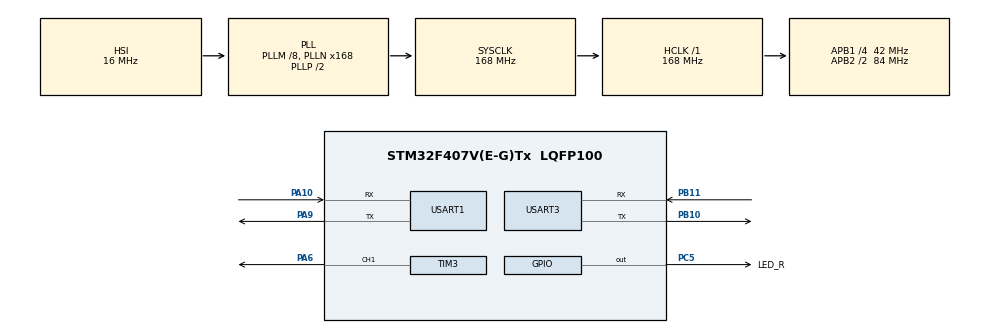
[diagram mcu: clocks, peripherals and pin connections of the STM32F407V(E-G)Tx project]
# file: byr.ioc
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Dma.Request0=USART1_RX
Dma.Request1=USART1_TX
Dma.Request2=USART3_RX
Dma.Request3=USART3_TX
Dma.USART1_RX.0.Direction=DMA_PERIPH_TO_MEMORY
Dma.USART1_RX.0.FIFOMode=DMA_FIFOMODE_DISABLE
Dma.USART1_RX.0.Instance=DMA2_Stream2
Dma.USART1_RX.0.MemDataAlignment=DMA_MDATAALIGN_BYTE
Dma.USART1_RX.0.MemInc=DMA_MINC_ENABLE
Dma.USART1_RX.0.Mode=DMA_CIRCULAR
Dma.USART1_RX.0.PeriphDataAlignment=DMA_PDATAALIGN_BYTE
Dma.USART1_RX.0.PeriphInc=DMA_PINC_DISABLE
Dma.USART1_RX.0.Priority=DMA_PRIORITY_LOW
Dma.USART1_TX.1.Direction=DMA_MEMORY_TO_PERIPH
Dma.USART1_TX.1.FIFOMode=DMA_FIFOMODE_DISABLE
Dma.USART1_TX.1.Instance=DMA2_Stream7
Dma.USART1_TX.1.MemDataAlignment=DMA_MDATAALIGN_BYTE
Dma.USART1_TX.1.MemInc=DMA_MINC_ENABLE
Dma.USART1_TX.1.Mode=DMA_NORMAL
Dma.USART1_TX.1.PeriphDataAlignment=DMA_PDATAALIGN_BYTE
Dma.USART1_TX.1.PeriphInc=DMA_PINC_DISABLE
Dma.USART1_TX.1.Priority=DMA_PRIORITY_LOW
Dma.USART3_RX.2.Direction=DMA_PERIPH_TO_MEMORY
Dma.USART3_RX.2.FIFOMode=DMA_FIFOMODE_DISABLE
Dma.USART3_RX.2.Instance=DMA1_Stream1
Dma.USART3_RX.2.MemDataAlignment=DMA_MDATAALIGN_BYTE
Dma.USART3_RX.2.MemInc=DMA_MINC_ENABLE
Dma.USART3_RX.2.Mode=DMA_CIRCULAR
Dma.USART3_RX.2.PeriphDataAlignment=DMA_PDATAALIGN_BYTE
Dma.USART3_RX.2.PeriphInc=DMA_PINC_DISABLE
Dma.USART3_RX.2.Priority=DMA_PRIORITY_LOW
Dma.USART3_TX.3.Direction=DMA_MEMORY_TO_PERIPH
Dma.USART3_TX.3.FIFOMode=DMA_FIFOMODE_DISABLE
Dma.USART3_TX.3.Instance=DMA1_Stream3
Dma.USART3_TX.3.MemDataAlignment=DMA_MDATAALIGN_BYTE
Dma.USART3_TX.3.MemInc=DMA_MINC_ENABLE
Dma.USART3_TX.3.Mode=DMA_NORMAL
Dma.USART3_TX.3.PeriphDataAlignment=DMA_PDATAALIGN_BYTE
Dma.USART3_TX.3.PeriphInc=DMA_PINC_DISABLE
Dma.USART3_TX.3.Priority=DMA_PRIORITY_LOW
Mcu.Family=STM32F4
Mcu.Name=STM32F407V(E-G)Tx
Mcu.Package=LQFP100
NVIC.DMA1_Stream1_IRQn=true\:0\:0\:false\:false\:true\:false\:true\:true
NVIC.DMA1_Stream3_IRQn=true\:0\:0\:false\:false\:true\:false\:true\:true
NVIC.DMA2_Stream2_IRQn=true\:0\:0\:false\:false\:true\:false\:true\:true
NVIC.DMA2_Stream7_IRQn=true\:0\:0\:false\:false\:true\:false\:true\:true
NVIC.PriorityGroup=NVIC_PRIORITYGROUP_4
NVIC.TIM4_IRQn=true\:2\:0\:true\:false\:true\:true\:true\:true
NVIC.USART1_IRQn=true\:3\:0\:true\:false\:true\:false\:true\:true
NVIC.USART3_IRQn=true\:0\:0\:false\:false\:true\:false\:true\:true
PA10.Mode=Asynchronous
PA10.Signal=USART1_RX
PA13.Mode=Serial_Wire
PA13.Signal=SYS_JTMS-SWDIO
PA14.Mode=Serial_Wire
PA14.Signal=SYS_JTCK-SWCLK
PA6.Signal=S_TIM3_CH1
PA9.Mode=Asynchronous
PA9.Signal=USART1_TX
PB10.Mode=Asynchronous
PB10.Signal=USART3_TX
PB11.Mode=Asynchronous
PB11.Signal=USART3_RX
PC14-OSC32_IN.Mode=LSE-External-Oscillator
PC14-OSC32_IN.Signal=RCC_OSC32_IN
PC15-OSC32_OUT.Mode=LSE-External-Oscillator
PC15-OSC32_OUT.Signal=RCC_OSC32_OUT
PC5.GPIO_Label=LED_R
PC5.Signal=GPIO_Output
PH0-OSC_IN.Mode=HSE-External-Oscillator
PH0-OSC_IN.Signal=RCC_OSC_IN
PH1-OSC_OUT.Mode=HSE-External-Oscillator
PH1-OSC_OUT.Signal=RCC_OSC_OUT
ProjectManager.HeapSize=0x1000
ProjectManager.StackSize=0x1200
ProjectManager.TargetToolchain=CMake
RCC.48MHZClocksFreq_Value=84000000
RCC.AHBFreq_Value=168000000
RCC.APB1CLKDivider=RCC_HCLK_DIV4
RCC.APB1Freq_Value=42000000
RCC.APB1TimFreq_Value=84000000
RCC.APB2CLKDivider=RCC_HCLK_DIV2
RCC.APB2Freq_Value=84000000
RCC.APB2TimFreq_Value=168000000
RCC.CortexFreq_Value=168000000
RCC.HCLKFreq_Value=168000000
RCC.HSE_VALUE=25000000
RCC.HSI_VALUE=16000000
RCC.PLLM=8
RCC.PLLN=168
RCC.SYSCLKFreq_VALUE=168000000
RCC.SYSCLKSource=RCC_SYSCLKSOURCE_PLLCLK
RCC.VCOOutputFreq_Value=336000000
SH.S_TIM3_CH1.0=TIM3_CH1,PWM Generation1 CH1
TIM3.Channel-PWM\ Generation1\ CH1=TIM_CHANNEL_1
TIM3.Period=999
TIM3.Prescaler=0
TIM3.Pulse-PWM\ Generation1\ CH1=4999
TIM4.ClockDivision=TIM_CLOCKDIVISION_DIV4
TIM4.Period=999
TIM4.Prescaler=20999
USART1.VirtualMode=VM_ASYNC
USART3.VirtualMode=VM_ASYNC
VP_TIM3_VS_ClockSourceINT.Mode=Internal
VP_TIM4_VS_ClockSourceINT.Mode=Internal
board=custom

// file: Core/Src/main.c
/* USER CODE BEGIN Header */
/**
  ******************************************************************************
  * @file           : main.c
  * @brief          : Main program body
  ******************************************************************************
  * @attention
  *
  * Copyright (c) 2025 STMicroelectronics.
  * All rights reserved.P
  *
  * This software is licensed under terms that can be found in the LICENSE file
  * in the root directory of this software component.
  * If no LICENSE file comes with this software, it is provided AS-IS.
  *
  ******************************************************************************
  */
/* USER CODE END Header */
#include "main.h"
#include "dma.h"
#include "tim.h"
#include "usart.h"
#include "gpio.h"

/* USER CODE BEGIN Includes */
#include "cmd.h"
#include "led.h"
/* USER CODE END Includes */

void SystemClock_Config(void);

int main(void)
{

  /* MCU Configuration--------------------------------------------------------*/

  /* Reset of all peripherals, Initializes the Flash interface and the Systick. */
  HAL_Init();

  /* Configure the system clock */
  SystemClock_Config();

  /* Initialize all configured peripherals */
  MX_GPIO_Init();
  MX_DMA_Init();
  MX_USART1_UART_Init();
  MX_USART3_UART_Init();
  MX_TIM3_Init();
  MX_TIM4_Init();
  /* USER CODE BEGIN 2 */
  CMD_Init();
  LED_Init();
  HAL_Delay(100);
  /* USER CODE END 2 */

  /* Infinite loop */
  /* USER CODE BEGIN WHILE */
  while (1)
  {
    CMD_Run();
    Board_Alive();
    /* USER CODE END WHILE */

  }
}

void SystemClock_Config(void)
{
  RCC_OscInitTypeDef RCC_OscInitStruct = {0};
  RCC_ClkInitTypeDef RCC_ClkInitStruct = {0};

  /** Configure the main internal regulator output voltage
  */
  __HAL_RCC_PWR_CLK_ENABLE();
  __HAL_PWR_VOLTAGESCALING_CONFIG(PWR_REGULATOR_VOLTAGE_SCALE1);

  /** Initializes the RCC Oscillators according to the specified parameters
  * in the RCC_OscInitTypeDef structure.
  */
  RCC_OscInitStruct.OscillatorType = RCC_OSCILLATORTYPE_HSI;
  RCC_OscInitStruct.HSIState = RCC_HSI_ON;
  RCC_OscInitStruct.HSICalibrationValue = RCC_HSICALIBRATION_DEFAULT;
  RCC_OscInitStruct.PLL.PLLState = RCC_PLL_ON;
  RCC_OscInitStruct.PLL.PLLSource = RCC_PLLSOURCE_HSI;
  RCC_OscInitStruct.PLL.PLLM = 8;
  RCC_OscInitStruct.PLL.PLLN = 168;
  RCC_OscInitStruct.PLL.PLLP = RCC_PLLP_DIV2;
  RCC_OscInitStruct.PLL.PLLQ = 4;
  if (HAL_RCC_OscConfig(&RCC_OscInitStruct) != HAL_OK)
  {
    Error_Handler();
  }

  /** Initializes the CPU, AHB and APB buses clocks
  */
  RCC_ClkInitStruct.ClockType = RCC_CLOCKTYPE_HCLK|RCC_CLOCKTYPE_SYSCLK
                              |RCC_CLOCKTYPE_PCLK1|RCC_CLOCKTYPE_PCLK2;
  RCC_ClkInitStruct.SYSCLKSource = RCC_SYSCLKSOURCE_PLLCLK;
  RCC_ClkInitStruct.AHBCLKDivider = RCC_SYSCLK_DIV1;
  RCC_ClkInitStruct.APB1CLKDivider = RCC_HCLK_DIV4;
  RCC_ClkInitStruct.APB2CLKDivider = RCC_HCLK_DIV2;

  if (HAL_RCC_ClockConfig(&RCC_ClkInitStruct, FLASH_LATENCY_5) != HAL_OK)
  {
    Error_Handler();
  }
}

void Error_Handler(void)
{
  __disable_irq();
  while (1)
  {
  }
}
